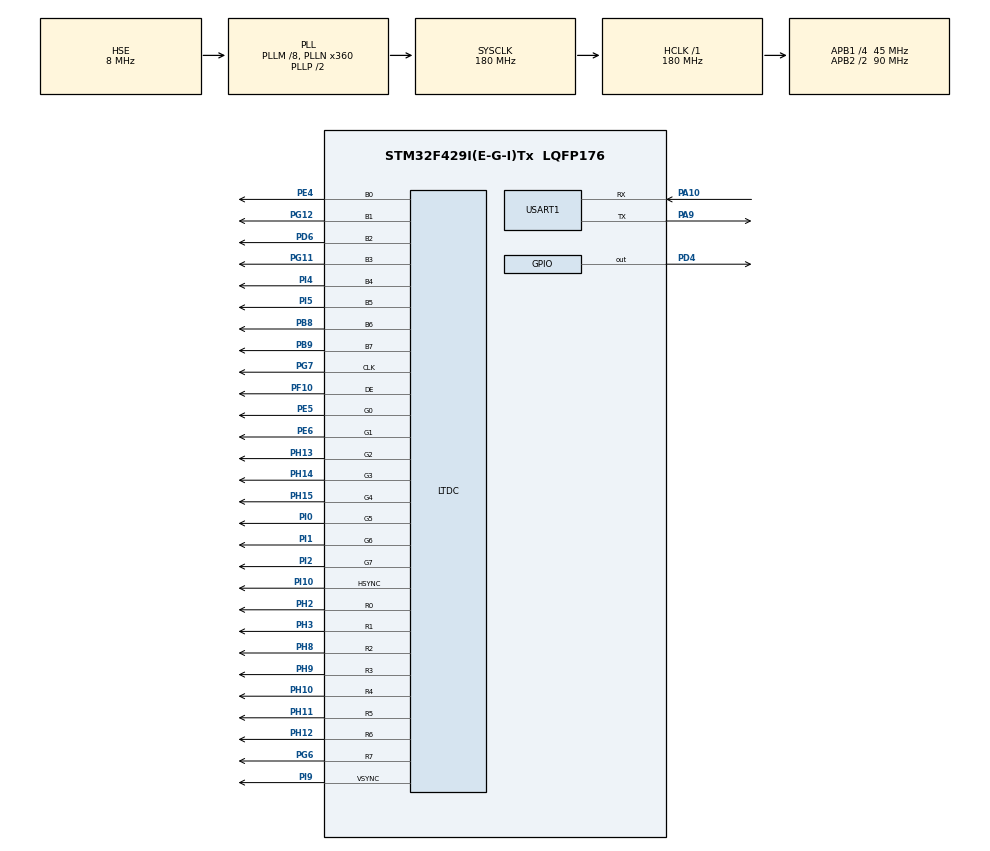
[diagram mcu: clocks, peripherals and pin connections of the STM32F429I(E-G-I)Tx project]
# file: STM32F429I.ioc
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LTDC.ActiveH=272
LTDC.ActiveW=480
LTDC.Alpha_L0=0xFF
LTDC.Alpha_L1=0
LTDC.BlendingFactor1_L0=LTDC_BLENDING_FACTOR1_CA
LTDC.BlendingFactor1_L1=LTDC_BLENDING_FACTOR1_PAxCA
LTDC.BlendingFactor2_L0=LTDC_BLENDING_FACTOR2_CA
LTDC.BlendingFactor2_L1=LTDC_BLENDING_FACTOR2_PAxCA
LTDC.FBStartAdress_L0=0xD0000000
LTDC.FBStartAdress_L1=0xD0060000
LTDC.HBP=2
LTDC.HFP=2
LTDC.HSync=10
LTDC.ImageHeight_L0=272
LTDC.ImageHeight_L1=272
LTDC.ImageWidth_L0=480
LTDC.ImageWidth_L1=480
LTDC.PixelFormat_L0=LTDC_PIXEL_FORMAT_RGB565
LTDC.PixelFormat_L1=LTDC_PIXEL_FORMAT_RGB565
LTDC.VBP=10
LTDC.VFP=2
LTDC.VSync=2
LTDC.WindowX0_L0=0
LTDC.WindowX0_L1=0
LTDC.WindowX1_L0=480
LTDC.WindowX1_L1=272
LTDC.WindowY0_L0=0
LTDC.WindowY0_L1=0
LTDC.WindowY1_L0=272
LTDC.WindowY1_L1=480
Mcu.Family=STM32F4
Mcu.Name=STM32F429I(E-G-I)Tx
Mcu.Package=LQFP176
NVIC.PriorityGroup=NVIC_PRIORITYGROUP_4
PA10.Mode=Asynchronous
PA10.Signal=USART1_RX
PA9.Mode=Asynchronous
PA9.Signal=USART1_TX
PB8.GPIO_Speed=GPIO_SPEED_FAST
PB8.Mode=RGB888
PB8.Signal=LTDC_B6
PB9.GPIO_Speed=GPIO_SPEED_FAST
PB9.Mode=RGB888
PB9.Signal=LTDC_B7
PD4.Signal=GPIO_Output
PD6.GPIO_Speed=GPIO_SPEED_FAST
PD6.Mode=RGB888
PD6.Signal=LTDC_B2
PE4.GPIO_Speed=GPIO_SPEED_FAST
PE4.Mode=RGB888
PE4.Signal=LTDC_B0
PE5.GPIO_Speed=GPIO_SPEED_FAST
PE5.Mode=RGB888
PE5.Signal=LTDC_G0
PE6.GPIO_Speed=GPIO_SPEED_FAST
PE6.Mode=RGB888
PE6.Signal=LTDC_G1
PF10.GPIO_Speed=GPIO_SPEED_FAST
PF10.Mode=RGB888
PF10.Signal=LTDC_DE
PG11.GPIO_Speed=GPIO_SPEED_FAST
PG11.Mode=RGB888
PG11.Signal=LTDC_B3
PG12.GPIO_Speed=GPIO_SPEED_FAST
PG12.Mode=RGB888
PG12.Signal=LTDC_B1
PG6.GPIO_Speed=GPIO_SPEED_FAST
PG6.Mode=RGB888
PG6.Signal=LTDC_R7
PG7.GPIO_Speed=GPIO_SPEED_FAST
PG7.Mode=RGB888
PG7.Signal=LTDC_CLK
PH0/OSC_IN.Mode=HSE-External-Oscillator
PH0/OSC_IN.Signal=RCC_OSC_IN
PH1/OSC_OUT.Mode=HSE-External-Oscillator
PH1/OSC_OUT.Signal=RCC_OSC_OUT
PH10.GPIO_Speed=GPIO_SPEED_FAST
PH10.Mode=RGB888
PH10.Signal=LTDC_R4
PH11.GPIO_Speed=GPIO_SPEED_FAST
PH11.Mode=RGB888
PH11.Signal=LTDC_R5
PH12.GPIO_Speed=GPIO_SPEED_FAST
PH12.Mode=RGB888
PH12.Signal=LTDC_R6
PH13.GPIO_Speed=GPIO_SPEED_FAST
PH13.Mode=RGB888
PH13.Signal=LTDC_G2
PH14.GPIO_Speed=GPIO_SPEED_FAST
PH14.Mode=RGB888
PH14.Signal=LTDC_G3
PH15.GPIO_Speed=GPIO_SPEED_FAST
PH15.Mode=RGB888
PH15.Signal=LTDC_G4
PH2.GPIO_Speed=GPIO_SPEED_FAST
PH2.Mode=RGB888
PH2.Signal=LTDC_R0
PH3.GPIO_Speed=GPIO_SPEED_FAST
PH3.Mode=RGB888
PH3.Signal=LTDC_R1
PH8.GPIO_Speed=GPIO_SPEED_FAST
PH8.Mode=RGB888
PH8.Signal=LTDC_R2
PH9.GPIO_Speed=GPIO_SPEED_FAST
PH9.Mode=RGB888
PH9.Signal=LTDC_R3
PI0.GPIO_Speed=GPIO_SPEED_FAST
PI0.Mode=RGB888
PI0.Signal=LTDC_G5
PI1.GPIO_Speed=GPIO_SPEED_FAST
PI1.Mode=RGB888
PI1.Signal=LTDC_G6
PI10.GPIO_Speed=GPIO_SPEED_FAST
PI10.Mode=RGB888
PI10.Signal=LTDC_HSYNC
PI2.GPIO_Speed=GPIO_SPEED_FAST
PI2.Mode=RGB888
PI2.Signal=LTDC_G7
PI4.GPIO_Speed=GPIO_SPEED_FAST
PI4.Mode=RGB888
PI4.Signal=LTDC_B4
PI5.GPIO_Speed=GPIO_SPEED_FAST
PI5.Mode=RGB888
PI5.Signal=LTDC_B5
PI9.GPIO_Speed=GPIO_SPEED_FAST
PI9.Mode=RGB888
PI9.Signal=LTDC_VSYNC
ProjectManager.TargetToolchain=MDK-ARM V5
RCC.48MHZClocksFreq_Value=90000000
RCC.AHBFreq_Value=180000000
RCC.APB1CLKDivider=RCC_HCLK_DIV4
RCC.APB1Freq_Value=45000000
RCC.APB1TimFreq_Value=90000000
RCC.APB2CLKDivider=RCC_HCLK_DIV2
RCC.APB2Freq_Value=90000000
RCC.APB2TimFreq_Value=180000000
RCC.CortexFreq_Value=180000000
RCC.HCLKFreq_Value=180000000
RCC.HSE_VALUE=8000000
RCC.HSI_VALUE=16000000
RCC.LSE_VALUE=32768
RCC.PLLM=8
RCC.PLLN=360
RCC.PLLSAIDivR=RCC_PLLSAIDIVR_8
RCC.PLLSAIN=192
RCC.PLLSourceVirtual=RCC_PLLSOURCE_HSE
RCC.SYSCLKFreq_VALUE=180000000
RCC.SYSCLKSource=RCC_SYSCLKSOURCE_PLLCLK
RCC.VCOOutputFreq_Value=360000000
board=STM32F429I

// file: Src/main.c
/**
  ******************************************************************************
  * File Name          : main.c
  * Description        : Main program body
  ******************************************************************************
  *
  * COPYRIGHT(c) 2016 STMicroelectronics
  *
  * Redistribution and use in source and binary forms, with or without modification,
  * are permitted provided that the following conditions are met:
  *   1. Redistributions of source code must retain the above copyright notice,
  *      this list of conditions and the following disclaimer.
  *   2. Redistributions in binary form must reproduce the above copyright notice,
  *      this list of conditions and the following disclaimer in the documentation
  *      and/or other materials provided with the distribution.
  *   3. Neither the name of STMicroelectronics nor the names of its contributors
  *      may be used to endorse or promote products derived from this software
  *      without specific prior written permission.
  *
  * THIS SOFTWARE IS PROVIDED BY THE COPYRIGHT HOLDERS AND CONTRIBUTORS "AS IS"
  * AND ANY EXPRESS OR IMPLIED WARRANTIES, INCLUDING, BUT NOT LIMITED TO, THE
  * IMPLIED WARRANTIES OF MERCHANTABILITY AND FITNESS FOR A PARTICULAR PURPOSE ARE
  * DISCLAIMED. IN NO EVENT SHALL THE COPYRIGHT HOLDER OR CONTRIBUTORS BE LIABLE
  * FOR ANY DIRECT, INDIRECT, INCIDENTAL, SPECIAL, EXEMPLARY, OR CONSEQUENTIAL
  * DAMAGES (INCLUDING, BUT NOT LIMITED TO, PROCUREMENT OF SUBSTITUTE GOODS OR
  * SERVICES; LOSS OF USE, DATA, OR PROFITS; OR BUSINESS INTERRUPTION) HOWEVER
  * CAUSED AND ON ANY THEORY OF LIABILITY, WHETHER IN CONTRACT, STRICT LIABILITY,
  * OR TORT (INCLUDING NEGLIGENCE OR OTHERWISE) ARISING IN ANY WAY OUT OF THE USE
  * OF THIS SOFTWARE, EVEN IF ADVISED OF THE POSSIBILITY OF SUCH DAMAGE.
  *
  ******************************************************************************
  */
#include "stm32f4xx_hal.h"
#include "ltdc.h"
#include "usart.h"
#include "gpio.h"

/* USER CODE BEGIN PV */
/* Private variables ---------------------------------------------------------*/

/* USER CODE END PV */

void SystemClock_Config(void);

/* USER CODE BEGIN PFP */
/* Private function prototypes -----------------------------------------------*/

/* USER CODE END PFP */

int main(void)
{

  /* MCU Configuration----------------------------------------------------------*/

  /* Reset of all peripherals, Initializes the Flash interface and the Systick. */
  HAL_Init();

  /* Configure the system clock */
  SystemClock_Config();

  /* Initialize all configured peripherals */
  MX_GPIO_Init();
  MX_LTDC_Init();
  MX_USART1_UART_Init();

  /* USER CODE BEGIN 2 */
	HAL_GPIO_WritePin(GPIOD,GPIO_PIN_4,GPIO_PIN_SET);
  /* USER CODE END 2 */

  /* Infinite loop */
  while (1)
  {

	}

}

/** System Clock Configuration
*/
void SystemClock_Config(void)
{

  RCC_OscInitTypeDef RCC_OscInitStruct;
  RCC_ClkInitTypeDef RCC_ClkInitStruct;
  RCC_PeriphCLKInitTypeDef PeriphClkInitStruct;

  __PWR_CLK_ENABLE();

  __HAL_PWR_VOLTAGESCALING_CONFIG(PWR_REGULATOR_VOLTAGE_SCALE1);

  RCC_OscInitStruct.OscillatorType = RCC_OSCILLATORTYPE_HSE;
  RCC_OscInitStruct.HSEState = RCC_HSE_ON;
  RCC_OscInitStruct.PLL.PLLState = RCC_PLL_ON;
  RCC_OscInitStruct.PLL.PLLSource = RCC_PLLSOURCE_HSE;
  RCC_OscInitStruct.PLL.PLLM = 8;
  RCC_OscInitStruct.PLL.PLLN = 360;
  RCC_OscInitStruct.PLL.PLLP = RCC_PLLP_DIV2;
  RCC_OscInitStruct.PLL.PLLQ = 4;
  HAL_RCC_OscConfig(&RCC_OscInitStruct);

  HAL_PWREx_ActivateOverDrive();

  RCC_ClkInitStruct.ClockType = RCC_CLOCKTYPE_SYSCLK|RCC_CLOCKTYPE_PCLK1
                              |RCC_CLOCKTYPE_PCLK2;
  RCC_ClkInitStruct.SYSCLKSource = RCC_SYSCLKSOURCE_PLLCLK;
  RCC_ClkInitStruct.AHBCLKDivider = RCC_SYSCLK_DIV1;
  RCC_ClkInitStruct.APB1CLKDivider = RCC_HCLK_DIV4;
  RCC_ClkInitStruct.APB2CLKDivider = RCC_HCLK_DIV2;
  HAL_RCC_ClockConfig(&RCC_ClkInitStruct, FLASH_LATENCY_5);

  PeriphClkInitStruct.PeriphClockSelection = RCC_PERIPHCLK_LTDC;
  PeriphClkInitStruct.PLLSAI.PLLSAIN = 192;
  PeriphClkInitStruct.PLLSAI.PLLSAIR = 2;
  PeriphClkInitStruct.PLLSAIDivR = RCC_PLLSAIDIVR_8;
  HAL_RCCEx_PeriphCLKConfig(&PeriphClkInitStruct);

  HAL_SYSTICK_Config(HAL_RCC_GetHCLKFreq()/1000);

  HAL_SYSTICK_CLKSourceConfig(SYSTICK_CLKSOURCE_HCLK);

  /* SysTick_IRQn interrupt configuration */
  HAL_NVIC_SetPriority(SysTick_IRQn, 0, 0);
}

/************************ (C) COPYRIGHT STMicroelectronics *****END OF FILE****/
